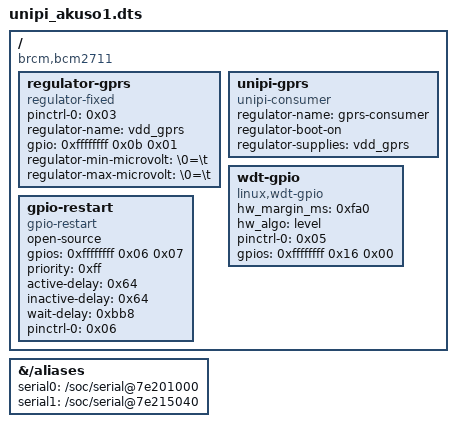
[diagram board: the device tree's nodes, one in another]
/dts-v1/;

/ {
	compatible = "brcm,bcm2711";

	fragment@0 {
		target = <0xffffffff>;

		__overlay__ {
			pinctrl-names = "default";
			pinctrl-0 = <0xffffffff>;
			status = "okay";
			linux,rs485-enabled-at-boot-time;
			uart-has-rtscts;
		};
	};

	fragment@1 {
		target = <0xffffffff>;

		__overlay__ {
			brcm,pins = <0x04 0x05 0x07>;
			brcm,pull = <0x00 0x02 0x00>;
		};
	};

	fragment@2 {
		target = <0xffffffff>;

		__overlay__ {
			pinctrl-names = "default";
			pinctrl-0 = <0x01 0x02>;
			status = "okay";
			linux,rs485-enabled-at-boot-time;
			uart-has-rtscts;
		};
	};

	fragment@3 {
		target = <0xffffffff>;

		__overlay__ {

			uart0_ovl_pins {
				brcm,pins = <0x0e 0x0f>;
				brcm,function = <0x04>;
				brcm,pull = <0x00 0x02>;
				phandle = <0x01>;
			};

			uart0_rts_ovl_pins {
				brcm,pins = <0x11>;
				brcm,function = <0x07>;
				brcm,pull = <0x00>;
				phandle = <0x02>;
			};
		};
	};

	fragment@4 {
		target = <0xffffffff>;

		__overlay__ {
			pinctrl-names = "default";
			pinctrl-0 = <0xffffffff>;
			status = "okay";
		};
	};

	fragment@5 {
		target = <0xffffffff>;

		__overlay__ {
			brcm,pins = <0x08 0x09>;
			brcm,pull = <0x00 0x02>;
		};
	};

	fragment@6 {
		target = <0xffffffff>;

		__overlay__ {
			brcm,pins = <0x10 0x1a>;
			brcm,function = <0x01 0x00>;
			brcm,pull = <0x00 0x00>;
		};
	};

	fragment@7 {
		target = <0xffffffff>;

		__overlay__ {
			#address-cells = <0x01>;
			#size-cells = <0x00>;
			pinctrl-names = "default";
			pinctrl-0 = <0xffffffff 0xffffffff>;
			cs-gpios = <0xffffffff 0x10 0x01>;
			dmas = <0xffffffff 0x17 0xffffffff 0x1b>;
			dma-names = "tx\0rx";
			status = "okay";

			unipispi@0 {
				compatible = "unipi,unipispi";
				reg = <0x00>;
				#address-cells = <0x01>;
				#size-cells = <0x00>;
				spi-max-frequency = <0xb71b00>;
				modbus-address = <0x01>;
				status = "okay";
				phandle = <0x07>;

				iogroup1 {
					reg = <0x01>;
					compatible = "unipi,unipi-mfd\0iogroup";
					interrupt-parent = <0xffffffff>;
					interrupts = <0x1a 0x01>;
					fw_variant = <0x2d10>;
					fw_name = "OEM-AKUSOLAR-1";
					board_name = "OEM-AKUSOLAR-1";
					cycle_counter = <0x3ff>;

					di {
						compatible = "unipi,gpio-di";
						gpio-controller;
						#gpio-cells = <0x02>;
						gpio-line-names = "DI1\0DI2\0DI3\0DI4";
						ngpio = <0x04>;
						value-reg = <0x00>;
						debounce-reg = <0x3f2>;
						counter-reg = <0x10>;
					};

					do {
						compatible = "unipi,gpio-do";
						ngpio = <0x04>;
						value-coil = <0x00>;
						gpio-controller;
						#gpio-cells = <0x02>;
						gpio-line-names = "DO1\0DO2\0DO3\0DO4";
					};

					ro {
						compatible = "unipi,gpio-ro";
						ngpio = <0x04>;
						value-coil = <0x04>;
						gpio-controller;
						#gpio-cells = <0x02>;
						gpio-line-names = "RO1\0RO2\0RO3\0RO4";
					};

					ao_chip {
						compatible = "unipi,ao";
						io-count = <0x02>;
						io-value-reg = <0x0a>;
					};

					led {
						compatible = "unipi,leds";
						coil-range = <0x0c 0x06>;
						label-prefix = "unipi:green:uled-x";
					};

					sysled {
						compatible = "unipi,leds";
						coil-range = <0x12 0x09>;
						label-prefix = "unipi:green:sysled-x";

						rs485-1-txled@0 {
							reg = <0x00>;
							linux,default-trigger = "ttyAMA1-tx";
						};

						rs485-1-rxled@1 {
							reg = <0x01>;
							linux,default-trigger = "ttyAMA1-rx";
						};

						rs485-2-txled@2 {
							reg = <0x02>;
							linux,default-trigger = "ttyAMA0-tx";
						};

						rs485-2-rxled@3 {
							reg = <0x03>;
							linux,default-trigger = "ttyAMA0-rx";
						};
					};
				};
			};
		};
	};

	fragment@8 {
		target = <0xffffffff>;

		__overlay__ {

			reg_gprs_pins@0 {
				brcm,pins = <0x0b>;
				brcm,function = <0x01>;
				brcm,pull = <0x00>;
				phandle = <0x03>;
			};
		};
	};

	fragment@9 {
		target-path = "/";

		__overlay__ {

			regulator-gprs {
				pinctrl-names = "default";
				pinctrl-0 = <0x03>;
				compatible = "regulator-fixed";
				regulator-name = "vdd_gprs";
				gpio = <0xffffffff 0x0b 0x01>;
				regulator-min-microvolt = "\0=\t";
				regulator-max-microvolt = "\0=\t";
				phandle = <0x08>;
			};

			unipi-gprs {
				compatible = "unipi-consumer";
				regulator-name = "gprs-consumer";
				regulator-boot-on;
				regulator-supplies = "vdd_gprs";
			};
		};
	};

	fragment@10 {
		target = <0xffffffff>;

		__overlay__ {
			status = "disabled";
		};
	};

	fragment@11 {
		target = <0xffffffff>;

		__overlay__ {
			pinctrl-names = "default";
			pinctrl-0 = <0xffffffff 0xffffffff 0x04>;
			status = "okay";
		};
	};

	fragment@12 {
		target = <0xffffffff>;

		__overlay__ {
			brcm,pins = <0x20 0x21>;
			brcm,function = <0x02>;
			brcm,pull = <0x00 0x02>;
			status = "okay";
		};
	};

	fragment@13 {
		target = <0xffffffff>;

		__overlay__ {

			fake_bt_cts {
				brcm,pins = <0x1f>;
				brcm,function = <0x01>;
				phandle = <0x04>;
			};
		};
	};

	fragment@14 {
		target-path = "/aliases";

		__overlay__ {
			serial0 = "/soc/serial@7e201000";
			serial1 = "/soc/serial@7e215040";
		};
	};

	fragment@15 {
		target = <0xffffffff>;

		__overlay__ {
			status = "okay";
		};
	};

	fragment@16 {
		target-path = "/";

		__overlay__ {

			wdt-gpio {
				compatible = "linux,wdt-gpio";
				hw_margin_ms = <0xfa0>;
				hw_algo = "level";
				pinctrl-names = "default";
				pinctrl-0 = <0x05>;
				gpios = <0xffffffff 0x16 0x00>;
				status = "okay";
				phandle = <0x09>;
			};

			gpio-restart {
				compatible = "gpio-restart";
				open-source;
				gpios = <0xffffffff 0x06 0x07>;
				priority = <0xff>;
				active-delay = <0x64>;
				inactive-delay = <0x64>;
				wait-delay = <0xbb8>;
				pinctrl-names = "default";
				pinctrl-0 = <0x06>;
				status = "okay";
				phandle = <0x0a>;
			};
		};
	};

	fragment@17 {
		target = <0xffffffff>;

		__overlay__ {

			wd-pins {
				brcm,pins = <0x16>;
				brcm,function = <0x01>;
				phandle = <0x05>;
			};

			reset-pins {
				brcm,pins = <0x06>;
				brcm,function = <0x00>;
				phandle = <0x06>;
			};
		};
	};

	__symbols__ {
		uart0_pins = "/fragment@3/__overlay__/uart0_ovl_pins";
		uart0_rts_pins = "/fragment@3/__overlay__/uart0_rts_ovl_pins";
		unipispi6_0 = "/fragment@7/__overlay__/unipispi@0";
		reg_gprs_pins = "/fragment@8/__overlay__/reg_gprs_pins@0";
		reg_gprs = "/fragment@9/__overlay__/regulator-gprs";
		fake_bt_cts = "/fragment@13/__overlay__/fake_bt_cts";
		wdt_gpio = "/fragment@16/__overlay__/wdt-gpio";
		gpio_restart = "/fragment@16/__overlay__/gpio-restart";
		wd_pins = "/fragment@17/__overlay__/wd-pins";
		reset_pins = "/fragment@17/__overlay__/reset-pins";
	};

	__fixups__ {
		uart3 = "/fragment@0:target:0";
		uart3_pins = "/fragment@0/__overlay__:pinctrl-0:0\0/fragment@1:target:0";
		uart0 = "/fragment@2:target:0";
		gpio = "/fragment@3:target:0\0/fragment@7/__overlay__:cs-gpios:0\0/fragment@7/__overlay__/unipispi@0/iogroup1:interrupt-parent:0\0/fragment@8:target:0\0/fragment@9/__overlay__/regulator-gprs:gpio:0\0/fragment@13:target:0\0/fragment@16/__overlay__/wdt-gpio:gpios:0\0/fragment@16/__overlay__/gpio-restart:gpios:0\0/fragment@17:target:0";
		uart4 = "/fragment@4:target:0";
		uart4_pins = "/fragment@4/__overlay__:pinctrl-0:0\0/fragment@5:target:0";
		spi6_cs_pins = "/fragment@6:target:0\0/fragment@7/__overlay__:pinctrl-0:4";
		spi6 = "/fragment@7:target:0";
		spi6_pins = "/fragment@7/__overlay__:pinctrl-0:0";
		dma = "/fragment@7/__overlay__:dmas:0\0/fragment@7/__overlay__:dmas:8";
		bt = "/fragment@10:target:0";
		uart1 = "/fragment@11:target:0";
		uart1_pins = "/fragment@11/__overlay__:pinctrl-0:0\0/fragment@12:target:0";
		bt_pins = "/fragment@11/__overlay__:pinctrl-0:4";
		minibt = "/fragment@15:target:0";
	};

	__local_fixups__ {

		fragment@2 {

			__overlay__ {
				pinctrl-0 = <0x00 0x04>;
			};
		};

		fragment@9 {

			__overlay__ {

				regulator-gprs {
					pinctrl-0 = <0x00>;
				};
			};
		};

		fragment@11 {

			__overlay__ {
				pinctrl-0 = <0x08>;
			};
		};

		fragment@16 {

			__overlay__ {

				wdt-gpio {
					pinctrl-0 = <0x00>;
				};

				gpio-restart {
					pinctrl-0 = <0x00>;
				};
			};
		};
	};
};
